# STM32H747xx_CM4 register map
File version: 1.0
Registers are 32-bit, read-write, reset 0x0 unless marked. A register's access mark holds for its fields unless they carry their own. Offsets are from the block's base; [hi:lo] are bit positions; {n}, {i} and the like mark numbered series.

## DMA1
Base 0x40020000
Same registers: DMA2 0x40020400
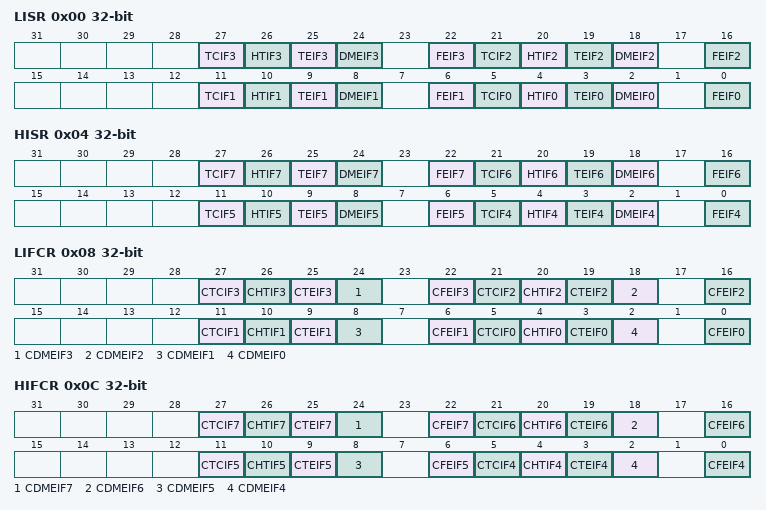
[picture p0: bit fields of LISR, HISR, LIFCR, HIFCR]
0x00 LISR — DMA low interrupt status register
  [27] TCIF3 — Stream 3 transfer complete interrupt flag
  [26] HTIF3 — Stream 3 half transfer interrupt flag
  [25] TEIF3 — Stream 3 transfer error interrupt flag
  [24] DMEIF3 — Stream 3 direct mode error interrupt flag
  [22] FEIF3 — Stream 3 FIFO error interrupt flag
  [21] TCIF2 — Stream 2 transfer complete interrupt flag
  [20] HTIF2 — Stream 2 half transfer interrupt flag
  [19] TEIF2 — Stream 2 transfer error interrupt flag
  [18] DMEIF2 — Stream 2 direct mode error interrupt flag
  [16] FEIF2 — Stream 2 FIFO error interrupt flag
  [11] TCIF1 — Stream 1 transfer complete interrupt flag
  [10] HTIF1 — Stream 1 half transfer interrupt flag
  [9] TEIF1 — Stream 1 transfer error interrupt flag
  [8] DMEIF1 — Stream 1 direct mode error interrupt flag
  [6] FEIF1 — Stream 1 FIFO error interrupt flag
  [5] TCIF0 — Stream 0 transfer complete interrupt flag
  [4] HTIF0 — Stream 0 half transfer interrupt flag
  [3] TEIF0 — Stream 0 transfer error interrupt flag
  [2] DMEIF0 — Stream 0 direct mode error interrupt flag
  [0] FEIF0 — Stream 0 FIFO error interrupt flag
0x04 HISR — DMA high interrupt status register
  [27] TCIF7 — Stream 7 transfer complete interrupt flag
  [26] HTIF7 — Stream 7 half transfer interrupt flag
  [25] TEIF7 — Stream 7 transfer error interrupt flag
  [24] DMEIF7 — Stream 7 direct mode error interrupt flag
  [22] FEIF7 — Stream 7 FIFO error interrupt flag
  [21] TCIF6 — Stream 6 transfer complete interrupt flag
  [20] HTIF6 — Stream 6 half transfer interrupt flag
  [19] TEIF6 — Stream 6 transfer error interrupt flag
  [18] DMEIF6 — Stream 6 direct mode error interrupt flag
  [16] FEIF6 — Stream 6 FIFO error interrupt flag
  [11] TCIF5 — Stream 5 transfer complete interrupt flag
  [10] HTIF5 — Stream 5 half transfer interrupt flag
  [9] TEIF5 — Stream 5 transfer error interrupt flag
  [8] DMEIF5 — Stream 5 direct mode error interrupt flag
  [6] FEIF5 — Stream 5 FIFO error interrupt flag
  [5] TCIF4 — Stream 4 transfer complete interrupt flag
  [4] HTIF4 — Stream 4 half transfer interrupt flag
  [3] TEIF4 — Stream 4 transfer error interrupt flag
  [2] DMEIF4 — Stream 4 direct mode error interrupt flag
  [0] FEIF4 — Stream 4 FIFO error interrupt flag
0x08 LIFCR — DMA low interrupt flag clear register
  [27] CTCIF3 — Stream 3 clear transfer complete interrupt flag
  [26] CHTIF3 — Stream 3 clear half transfer interrupt flag
  [25] CTEIF3 — Stream 3 clear transfer error interrupt flag
  [24] CDMEIF3 — Stream 3 clear direct mode error interrupt flag
  [22] CFEIF3 — Stream 3 clear FIFO error interrupt flag
  [21] CTCIF2 — Stream 2 clear transfer complete interrupt flag
  [20] CHTIF2 — Stream 2 clear half transfer interrupt flag
  [19] CTEIF2 — Stream 2 clear transfer error interrupt flag
  [18] CDMEIF2 — Stream 2 clear direct mode error interrupt flag
  [16] CFEIF2 — Stream 2 clear FIFO error interrupt flag
  [11] CTCIF1 — Stream 1 clear transfer complete interrupt flag
  [10] CHTIF1 — Stream 1 clear half transfer interrupt flag
  [9] CTEIF1 — Stream 1 clear transfer error interrupt flag
  [8] CDMEIF1 — Stream 1 clear direct mode error interrupt flag
  [6] CFEIF1 — Stream 1 clear FIFO error interrupt flag
  [5] CTCIF0 — Stream 0 clear transfer complete interrupt flag
  [4] CHTIF0 — Stream 0 clear half transfer interrupt flag
  [3] CTEIF0 — Stream 0 clear transfer error interrupt flag
  [2] CDMEIF0 — Stream 0 clear direct mode error interrupt flag
  [0] CFEIF0 — Stream 0 clear FIFO error interrupt flag
0x0C HIFCR — DMA high interrupt flag clear register
  [27] CTCIF7 — Stream 7 clear transfer complete interrupt flag
  [26] CHTIF7 — Stream 7 clear half transfer interrupt flag
  [25] CTEIF7 — Stream 7 clear transfer error interrupt flag
  [24] CDMEIF7 — Stream 7 clear direct mode error interrupt flag
  [22] CFEIF7 — Stream 7 clear FIFO error interrupt flag
  [21] CTCIF6 — Stream 6 clear transfer complete interrupt flag
  [20] CHTIF6 — Stream 6 clear half transfer interrupt flag
  [19] CTEIF6 — Stream 6 clear transfer error interrupt flag
  [18] CDMEIF6 — Stream 6 clear direct mode error interrupt flag
  [16] CFEIF6 — Stream 6 clear FIFO error interrupt flag
  [11] CTCIF5 — Stream 5 clear transfer complete interrupt flag
  [10] CHTIF5 — Stream 5 clear half transfer interrupt flag
  [9] CTEIF5 — Stream 5 clear transfer error interrupt flag
  [8] CDMEIF5 — Stream 5 clear direct mode error interrupt flag
  [6] CFEIF5 — Stream 5 clear FIFO error interrupt flag
  [5] CTCIF4 — Stream 4 clear transfer complete interrupt flag
  [4] CHTIF4 — Stream 4 clear half transfer interrupt flag
  [3] CTEIF4 — Stream 4 clear transfer error interrupt flag
  [2] CDMEIF4 — Stream 4 clear direct mode error interrupt flag
  [0] CFEIF4 — Stream 4 clear FIFO error interrupt flag
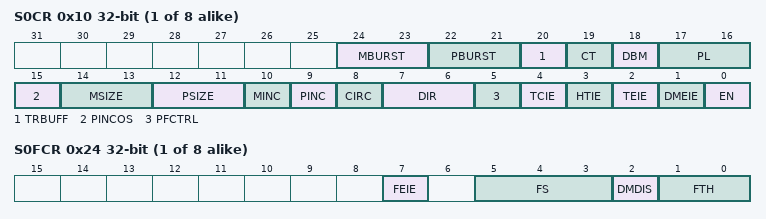
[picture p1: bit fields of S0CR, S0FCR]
{0x10+0x18*i} S{i}CR (i=0..7) — DMA stream x configuration register
  [24:23] MBURST — Memory burst transfer configuration
  [22:21] PBURST — Peripheral burst transfer configuration
  [20] TRBUFF — bufferable transfers enabled/disable
  [19] CT — Current target (only in double buffer mode)
  [18] DBM — Double buffer mode
  [17:16] PL — Priority level
  [15] PINCOS — Peripheral increment offset size
  [14:13] MSIZE — Memory data size
  [12:11] PSIZE
  [10] MINC — Memory increment mode
  [9] PINC — Peripheral increment mode
  [8] CIRC — Circular mode
  [7:6] DIR — Data transfer direction
  [5] PFCTRL — Peripheral flow controller
  [4] TCIE — Transfer complete interrupt enable
  [3] HTIE — Half transfer interrupt enable
  [2] TEIE — Transfer error interrupt enable
  [1] DMEIE — Direct mode error interrupt enable
  [0] EN — Stream enable / flag stream ready when read low
{0x14+0x18*i} S{i}NDTR (i=0..7) — DMA stream x number of data register
  [15:0] SxNDT — Number of data items to transfer
{0x18+0x18*i} S{i}PAR (i=0..7) — DMA stream x peripheral address register
  [31:0] PA — Peripheral Address
{0x1C+0x18*i} S{i}M0AR (i=0..7) — DMA stream x memory 0 address register
  [31:0] M0A — Memory 0 Address
{0x20+0x18*i} S{i}M1AR (i=0..7) — DMA stream x memory 1 address register
  [31:0] M1A — Memory 1 Address
{0x24+0x18*i} S{i}FCR (i=0..7) — DMA stream x FIFO control register
  [7] FEIE — FIFO error interrupt enable
  [5:3] FS — FIFO status
  [2] DMDIS — Direct mode disable
  [1:0] FTH — FIFO threshold selection
